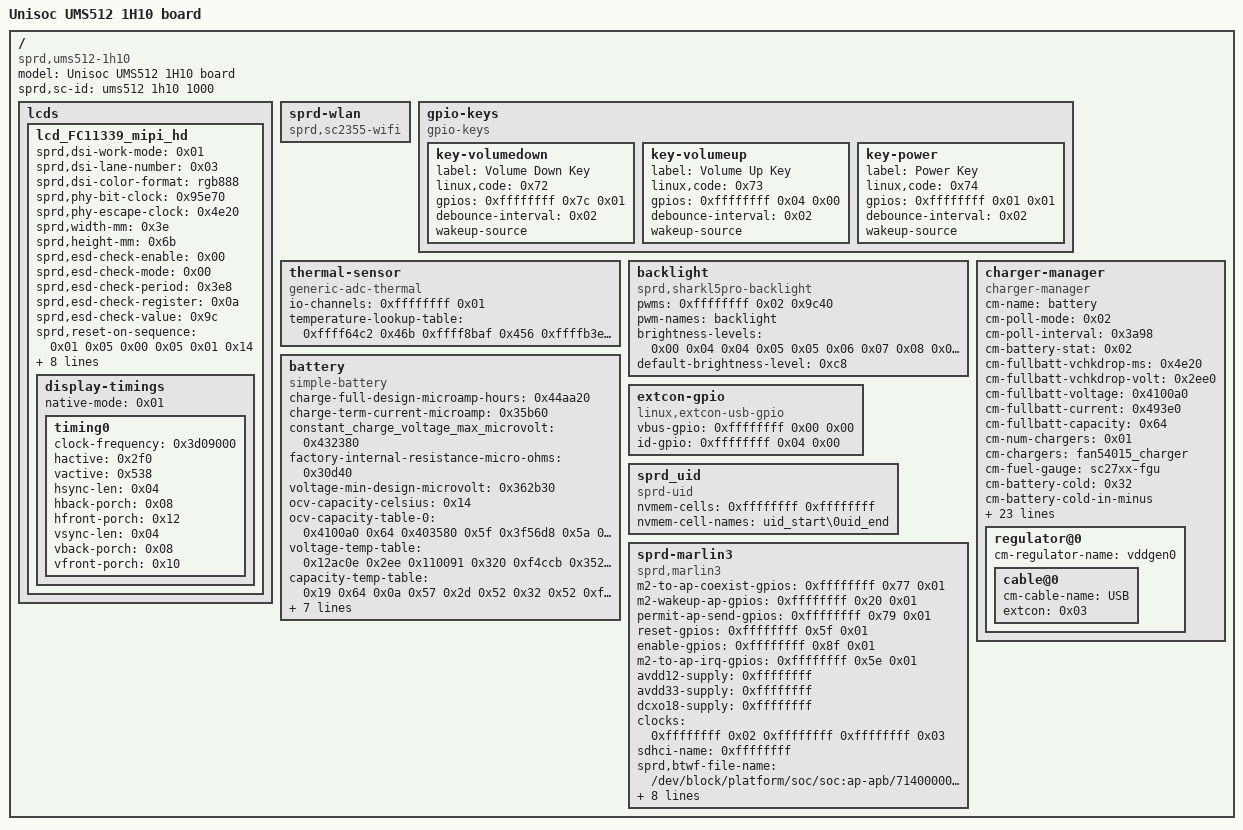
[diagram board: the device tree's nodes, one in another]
/dts-v1/;

/ {
	model = "Unisoc UMS512 1H10 board";
	compatible = "sprd,ums512-1h10";
	sprd,sc-id = "ums512 1h10 1000";

	fragment {
		target-path = "/";

		__overlay__ {

			lcds {

				lcd_FC11339_mipi_hd {
					sprd,dsi-work-mode = <0x01>;
					sprd,dsi-lane-number = <0x03>;
					sprd,dsi-color-format = "rgb888";
					sprd,phy-bit-clock = <0x95e70>;
					sprd,phy-escape-clock = <0x4e20>;
					sprd,width-mm = <0x3e>;
					sprd,height-mm = <0x6b>;
					sprd,esd-check-enable = <0x00>;
					sprd,esd-check-mode = <0x00>;
					sprd,esd-check-period = <0x3e8>;
					sprd,esd-check-register = <0x0a>;
					sprd,esd-check-value = <0x9c>;
					sprd,reset-on-sequence = <0x01 0x05 0x00 0x05 0x01 0x14>;
					sprd,reset-off-sequence = <0x00 0x05>;
					sprd,use-dcs-write;
					sprd,initial-command = [05 40 00 01 11 05 10 00 01 29];
					sprd,sleep-in-command = [15 10 00 01 28 15 40 00 01 10 29 00 00 02 b0 00 29 05 00 02 b1 01];
					sprd,sleep-out-command = [15 40 00 01 11 15 10 00 01 29 15 01 00 02 b0 00 15 01 00 02 b1 01];
					phandle = <0x18>;

					display-timings {
						native-mode = <0x01>;

						timing0 {
							clock-frequency = <0x3d09000>;
							hactive = <0x2f0>;
							vactive = <0x538>;
							hsync-len = <0x04>;
							hback-porch = <0x08>;
							hfront-porch = <0x12>;
							vsync-len = <0x04>;
							vback-porch = <0x08>;
							vfront-porch = <0x10>;
							phandle = <0x01>;
						};
					};
				};
			};

			sprd-wlan {
				compatible = "sprd,sc2355-wifi";
			};

			gpio-keys {
				compatible = "gpio-keys";

				key-volumedown {
					label = "Volume Down Key";
					linux,code = <0x72>;
					gpios = <0xffffffff 0x7c 0x01>;
					debounce-interval = <0x02>;
					wakeup-source;
				};

				key-volumeup {
					label = "Volume Up Key";
					linux,code = <0x73>;
					gpios = <0xffffffff 0x04 0x00>;
					debounce-interval = <0x02>;
					wakeup-source;
				};

				key-power {
					label = "Power Key";
					linux,code = <0x74>;
					gpios = <0xffffffff 0x01 0x01>;
					debounce-interval = <0x02>;
					wakeup-source;
				};
			};

			thermal-sensor {
				compatible = "generic-adc-thermal";
				#thermal-sensor-cells = <0x00>;
				io-channels = <0xffffffff 0x01>;
				io-channel-names = "sensor-channel";
				temperature-lookup-table = <0xffff64c2 0x46b 0xffff8baf 0x456 0xffffb3e8 0x432 0xffffedb9 0x3d7 0x277e 0x346 0x60e5 0x28e 0xaf7a 0x19d 0xd677 0x13c 0xfd7f 0xee 0x12484 0xb2 0x14b93 0x85 0x172a3 0x64 0x199b0 0x4b 0x1c0c9 0x39 0x1e7c8 0x2b>;
				phandle = <0x0f>;
			};

			backlight {
				compatible = "sprd,sharkl5pro-backlight";
				pwms = <0xffffffff 0x02 0x9c40>;
				pwm-names = "backlight";
				brightness-levels = <0x00 0x04 0x04 0x05 0x05 0x06 0x07 0x08 0x09 0x0a 0x0b 0x0c 0x0d 0x0e 0x0f 0x10 0x11 0x12 0x13 0x14 0x15 0x16 0x17 0x18 0x19 0x1a 0x1b 0x1c 0x1d 0x1e 0x1f 0x20 0x21 0x22 0x23 0x24 0x25 0x26 0x27 0x28 0x29 0x2a 0x2b 0x2c 0x2d 0x2e 0x2f 0x30 0x31 0x32 0x33 0x34 0x35 0x36 0x37 0x38 0x39 0x3a 0x3b 0x3c 0x3d 0x3e 0x3f 0x40 0x41 0x42 0x43 0x44 0x45 0x46 0x47 0x48 0x49 0x4a 0x4b 0x4c 0x4d 0x4e 0x4f 0x50 0x51 0x52 0x53 0x54 0x55 0x56 0x57 0x58 0x59 0x5a 0x5b 0x5c 0x5d 0x5e 0x5f 0x60 0x61 0x62 0x63 0x64 0x65 0x66 0x67 0x68 0x69 0x6a 0x6b 0x6c 0x6d 0x6e 0x6f 0x70 0x71 0x72 0x73 0x74 0x75 0x76 0x77 0x78 0x79 0x7a 0x7b 0x7c 0x7d 0x7e 0x7f 0x80 0x81 0x82 0x83 0x84 0x85 0x86 0x87 0x88 0x89 0x8a 0x8b 0x8c 0x8d 0x8e 0x8f 0x90 0x91 0x92 0x93 0x94 0x95 0x96 0x97 0x98 0x99 0x9a 0x9b 0x9c 0x9d 0x9e 0x9f 0xa0 0xa1 0xa2 0xa3 0xa4 0xa5 0xa6 0xa7 0xa8 0xa9 0xaa 0xab 0xac 0xad 0xae 0xaf 0xb0 0xb1 0xb2 0xb3 0xb4 0xb5 0xb6 0xb7 0xb8 0xb9 0xba 0xbb 0xbc 0xbd 0xbe 0xbf 0xc0 0xc1 0xc2 0xc3 0xc4 0xc5 0xc6 0xc7 0xc8 0xc9 0xca 0xcb 0xcc 0xcd 0xce 0xcf 0xd0 0xd1 0xd2 0xd3 0xd4 0xd5 0xd6 0xd7 0xd8 0xd9 0xda 0xdb 0xdc 0xdd 0xde 0xdf 0xe0 0xe1 0xe2 0xe3 0xe4 0xe5 0xe6 0xe7 0xe8 0xe9 0xea 0xeb 0xec 0xed 0xee 0xef 0xf0 0xf1 0xf2 0xf3 0xf4 0xf5 0xf6 0xf7 0xf8 0xf9 0xfa 0xfb 0xfc 0xfd 0xfd 0xfe 0xff>;
				default-brightness-level = <0xc8>;
				phandle = <0x14>;
			};

			battery {
				compatible = "simple-battery";
				charge-full-design-microamp-hours = <0x44aa20>;
				charge-term-current-microamp = <0x35b60>;
				constant_charge_voltage_max_microvolt = <0x432380>;
				factory-internal-resistance-micro-ohms = <0x30d40>;
				voltage-min-design-microvolt = <0x362b30>;
				ocv-capacity-celsius = <0x14>;
				ocv-capacity-table-0 = <0x4100a0 0x64 0x403580 0x5f 0x3f56d8 0x5a 0x3e83e8 0x55 0x3dbcb0 0x50 0x3d18a0 0x4b 0x4b9790 0x46 0x3bb528 0x41 0x3b2888 0x3c 0x3a8478 0x37 0x3a0390 0x32 0x39a1e8 0x2d 0x394fe0 0x28 0x391160 0x23 0x38dab0 0x1e 0x38b788 0x19 0x3884c0 0x14 0x384258 0x0f 0x37d8e0 0x0a 0x376f68 0x05 0x372918 0x00>;
				voltage-temp-table = <0x12ac0e 0x2ee 0x110091 0x320 0xf4ccb 0x352 0xd9e5a 0x384 0xc00db 0x3b6 0xa7dce 0x3e8 0x91a60 0x41a 0x7dba1 0x44c 0x6c0da 0x47e 0x5c97e 0x4b0 0x4f3d1 0x4e2 0x43ca3 0x514 0x39f71 0x546 0x319d3 0x578 0x2a7c0 0x5aa 0x247b8 0x5dc 0x1f62e 0x60e 0x1b198 0x640 0x176aa 0x672 0x1448a 0x6a4 0x11a34 0x6d6 0xf687 0x708>;
				capacity-temp-table = <0x19 0x64 0x0a 0x57 0x2d 0x52 0x32 0x52 0xfffffff6 0x58>;
				resistance-temp-table = <0x19 0x64 0x0a 0xb4 0x2d 0x31 0x32 0x29 0xfffffff6 0x1a4>;
				charge-sdp-current-microamp = <0x225510 0x16e360>;
				charge-dcp-current-microamp = <0x225510 0x1e8480>;
				charge-cdp-current-microamp = <0x225510 0x16e360>;
				charge-unknown-current-microamp = <0x225510 0x16e360>;
				phandle = <0x02>;
			};

			charger-manager {
				compatible = "charger-manager";
				cm-name = "battery";
				cm-poll-mode = <0x02>;
				cm-poll-interval = <0x3a98>;
				cm-battery-stat = <0x02>;
				cm-fullbatt-vchkdrop-ms = <0x4e20>;
				cm-fullbatt-vchkdrop-volt = <0x2ee0>;
				cm-fullbatt-voltage = <0x4100a0>;
				cm-fullbatt-current = <0x493e0>;
				cm-fullbatt-capacity = <0x64>;
				cm-num-chargers = <0x01>;
				cm-chargers = "fan54015_charger";
				cm-fuel-gauge = "sc27xx-fgu";
				cm-battery-cold = <0x32>;
				cm-battery-cold-in-minus;
				cm-battery-hot = <0x28a>;
				cm-battery-temp-diff = <0x32>;
				cm-charging-max = <0x112a880>;
				cm-discharging-max = <0x2932e0>;
				cm-wdt-interval = <0x3c>;
				cm-shutdown-voltage = <0x2f4d60>;
				cm-tickle-time-out = <0x258>;
				cm-one-cap-time = <0x1e>;
				cm-thermal-zone = "board-thmzone";
				cm-charge-voltage-max = <0x632ea0>;
				cm-charge-voltage-drop = <0xaae60>;
				cm-dcp-jeita-temp-table = <0x3e8 0x406 0x00 0x432380 0x47e 0x49c 0xaae60 0x432380 0x5aa 0x58c 0x225510 0x432380 0x640 0x622 0xaae60 0x3e8fa0>;
				cm-sdp-jeita-temp-table = <0x3e8 0x406 0x00 0x432380 0x47e 0x49c 0x7a120 0x432380 0x5aa 0x58c 0x225510 0x432380 0x640 0x622 0x7a120 0x3e8fa0>;
				cm-cdp-jeita-temp-table = <0x3e8 0x406 0x00 0x432380 0x47e 0x49c 0xaae60 0x432380 0x5aa 0x58c 0x225510 0x432380 0x640 0x622 0xaae60 0x3e8fa0>;
				cm-unknown-jeita-temp-table = <0x3e8 0x406 0x00 0x432380 0x47e 0x49c 0x7a120 0x432380 0x5aa 0x58c 0x225510 0x432380 0x640 0x622 0x7a120 0x3e8fa0>;
				monitored-battery = <0x02>;
				cm-capacity-track;
				cm-cap-remap-table = <0x01 0x02 0x02 0x02 0x03 0x01 0x62 0x63 0x02 0x63 0x64 0x02>;

				regulator@0 {
					cm-regulator-name = "vddgen0";

					cable@0 {
						cm-cable-name = "USB";
						extcon = <0x03>;
					};
				};
			};

			extcon-gpio {
				compatible = "linux,extcon-usb-gpio";
				vbus-gpio = <0xffffffff 0x00 0x00>;
				id-gpio = <0xffffffff 0x04 0x00>;
				phandle = <0x03>;
			};

			sprd_uid {
				compatible = "sprd-uid";
				nvmem-cells = <0xffffffff 0xffffffff>;
				nvmem-cell-names = "uid_start\0uid_end";
			};

			sprd-marlin3 {
				compatible = "sprd,marlin3";
				m2-to-ap-coexist-gpios = <0xffffffff 0x77 0x01>;
				m2-wakeup-ap-gpios = <0xffffffff 0x20 0x01>;
				permit-ap-send-gpios = <0xffffffff 0x79 0x01>;
				reset-gpios = <0xffffffff 0x5f 0x01>;
				enable-gpios = <0xffffffff 0x8f 0x01>;
				m2-to-ap-irq-gpios = <0xffffffff 0x5e 0x01>;
				avdd12-supply = <0xffffffff>;
				avdd33-supply = <0xffffffff>;
				dcxo18-supply = <0xffffffff>;
				clock-names = "clk_32k\0source\0enable";
				clocks = <0xffffffff 0x02 0xffffffff 0xffffffff 0x03>;
				sdhci-name = <0xffffffff>;
				sprd,btwf-file-name = "/dev/block/platform/soc/soc:ap-apb/71400000.sdio/by-name/wcnmodem";
				sprd,gnss-file-name = "/dev/block/platform/soc/soc:ap-apb/71400000.sdio/by-name/gnssmodem";
				adma-tx;
				adma-rx;
				avdd12-parent-bound-chip = <0x1a4c 0x01 0x00 0x01>;
				avdd12-bound-wbreq = <0x1ac8 0x1000 0x00 0x1000>;
				avdd33-bound-wbreq = <0x1acc 0x04 0x00 0x04>;
				phandle = <0x19>;
			};
		};
	};

	fragment@0 {
		target = <0xffffffff>;

		__overlay__ {
			bootargs_ext = "androidboot.hardware=ums512_1h10 androidboot.dtbo_idx=0";
		};
	};

	fragment@1 {
		target = <0xffffffff>;

		__overlay__ {

			logobuffer@9e000000 {
				reg = <0x00 0x9e000000 0x00 0x9e4000>;
				phandle = <0x17>;
			};

			drm-mem@e32ae000 {
				reg = <0x00 0xe32ae000 0x00 0xc800000>;
				phandle = <0x10>;
			};

			faceid-mem@efaae000 {
				reg = <0x00 0xefaae000 0x00 0x500000>;
				phandle = <0x11>;
			};

			vdsp-mem@f09ae000 {
				reg = <0x00 0xf09ae000 0x00 0x3700000>;
				phandle = <0x12>;
			};

			framebuffer-mem@fd708000 {
				reg = <0x00 0xfd708000 0x00 0x1e5a000>;
				phandle = <0x15>;
			};

			writeback-mem@ff562000 {
				reg = <0x00 0xff562000 0x00 0xa1e000>;
				phandle = <0x16>;
			};
		};
	};

	fragment@2 {
		target = <0xffffffff>;

		__overlay__ {
			cd-gpios = <0xffffffff 0x13 0x01>;
		};
	};

	fragment@3 {
		target = <0xffffffff>;

		__overlay__ {
			pinctrl-names = "gpio_121\0gpio_122\0gpio_123\0gpio_124\0gpio_125\0gpio_126\0gpio_144\0gpio_145\0gpio_146\0gpio_147\0gpio_16";
			pinctrl-0 = <0x04>;
			pinctrl-1 = <0x05>;
			pinctrl-2 = <0x06>;
			pinctrl-3 = <0x07>;
			pinctrl-4 = <0x08>;
			pinctrl-5 = <0x09>;
			pinctrl-6 = <0x0a>;
			pinctrl-7 = <0x0b>;
			pinctrl-8 = <0x0c>;
			pinctrl-9 = <0x0d>;
			pinctrl-10 = <0x0e>;

			keyout0 {
				pins = "SHARKL5PRO_KEYOUT0";
				function = "func4";
				phandle = <0x04>;
			};

			keyout1 {
				pins = "SHARKL5PRO_KEYOUT1";
				function = "func4";
				phandle = <0x05>;
			};

			keyout2 {
				pins = "SHARKL5PRO_KEYOUT2";
				function = "func4";
				phandle = <0x06>;
			};

			keyin0 {
				pins = "SHARKL5PRO_KEYIN0";
				function = "func4";
				phandle = <0x07>;
			};

			keyin1 {
				pins = "SHARKL5PRO_KEYIN1";
				function = "func4";
				phandle = <0x08>;
			};

			keyin2 {
				pins = "SHARKL5PRO_KEYIN2";
				function = "func4";
				phandle = <0x09>;
			};

			extint0 {
				pins = "SHARKL5PRO_EXTINT0";
				function = "func4";
				phandle = <0x0a>;
			};

			extint1 {
				pins = "SHARKL5PRO_EXTINT1";
				function = "func4";
				phandle = <0x0b>;
			};

			scl3 {
				pins = "SHARKL5PRO_SCL3";
				function = "func4";
				phandle = <0x0d>;
			};

			sda3 {
				pins = "SHARKL5PRO_SDA3";
				function = "func4";
				phandle = <0x0c>;
			};

			rffe1_sda {
				pins = "SHARKL5PRO_RFFE1_SDA";
				function = "func4";
				phandle = <0x0e>;
			};
		};
	};

	fragment@4 {
		target = <0xffffffff>;

		__overlay__ {

			board-thmzone {
				polling-delay-passive = <0x00>;
				polling-delay = <0x00>;
				thermal-sensors = <0x0f>;
				phandle = <0x1a>;
			};
		};
	};

	fragment@5 {
		target = <0xffffffff>;

		__overlay__ {

			heap@1 {
				reg = <0x01>;
				label = "carveout_mm";
				type = <0x02>;
				memory-region = <0x10>;
			};

			heap@4 {
				reg = <0x04>;
				label = "carveout_fd";
				type = <0x02>;
				memory-region = <0x11>;
			};

			heap@5 {
				reg = <0x05>;
				label = "carveout_vdsp";
				type = <0x02>;
				memory-region = <0x12>;
			};
		};
	};

	fragment@6 {
		target = <0xffffffff>;

		__overlay__ {
			status = "okay";
			clock-frequency = <0x61a80>;

			sensor-main@20 {
				compatible = "sprd,sensor-main";
				reg = <0x20>;
				clock-names = "clk_src\0sensor_eb\0clk_96m\0clk_76m8\0clk_48m\0clk_26m";
				clocks = <0xffffffff 0x02 0xffffffff 0x0d 0xffffffff 0x04 0xffffffff 0x10 0xffffffff 0x05 0xffffffff>;
				vddio-supply = <0xffffffff>;
				vddcama-supply = <0xffffffff>;
				vddcamd-supply = <0xffffffff>;
				vddcammot-supply = <0xffffffff>;
				avdd-gpios = <0xffffffff 0x19 0x00>;
				dvdd-gpios = <0xffffffff 0x0f 0x00>;
				reset-gpios = <0xffffffff 0x2c 0x00>;
				power-down-gpios = <0xffffffff 0x2e 0x00>;
				sprd,phyid = <0x00>;
				csi = <0xffffffff>;
				phandle = <0x1b>;
			};

			deputy-camera@21 {
				compatible = "deputy_camera, deputy_camera_i2c";
				reg = <0x21>;
				power_down_gpios_b = <0xffffffff 0x2e 0x00>;
				phandle = <0x1c>;
			};
		};
	};

	fragment@7 {
		target = <0xffffffff>;

		__overlay__ {
			status = "okay";
			clock-frequency = <0x61a80>;

			sensor-sub@6C {
				compatible = "sprd,sensor-sub";
				reg = <0x6c>;
				clock-names = "clk_src\0sensor_eb\0clk_96m\0clk_76m8\0clk_48m\0clk_26m";
				clocks = <0xffffffff 0x03 0xffffffff 0x0c 0xffffffff 0x04 0xffffffff 0x10 0xffffffff 0x05 0xffffffff>;
				vddio-supply = <0xffffffff>;
				vddcama-supply = <0xffffffff>;
				vddcamd-supply = <0xffffffff>;
				avdd-gpios = <0xffffffff 0x19 0x00>;
				dvdd-gpios = <0xffffffff 0x0f 0x00>;
				reset-gpios = <0xffffffff 0x29 0x00>;
				sprd,phyid = <0x04>;
				csi = <0xffffffff>;
				phandle = <0x1d>;
			};

			sensor-main2@2a {
				compatible = "sprd,sensor-main2";
				reg = <0x2a>;
				clock-names = "clk_src\0sensor_eb\0clk_96m\0clk_76m8\0clk_48m\0clk_26m";
				clocks = <0xffffffff 0x03 0xffffffff 0x0c 0xffffffff 0x04 0xffffffff 0x10 0xffffffff 0x05 0xffffffff>;
				vddio-supply = <0xffffffff>;
				vddcama-supply = <0xffffffff>;
				vddcamd-supply = <0xffffffff>;
				vddcammot-supply = <0xffffffff>;
				reset-gpios = <0xffffffff 0x29 0x00>;
				sprd,phyid = <0x02>;
				csi = <0xffffffff>;
				status = "okay";
				phandle = <0x1e>;
			};
		};
	};

	fragment@8 {
		target = <0xffffffff>;

		__overlay__ {
			status = "okay";
			clock-frequency = <0x61a80>;
		};
	};

	fragment@9 {
		target = <0xffffffff>;

		__overlay__ {
			status = "okay";

			hynitron-ts@5a {
				compatible = "hynitron,cst1xx";
				reg = <0x5a>;
				hynitron,panel-coords = <0x00 0x438 0x00 0x870>;
				hynitron,display-coords = <0x00 0x438 0x00 0x870>;
				hynitron,irq-gpio = <0xffffffff 0x90 0x00>;
				hynitron,rst-gpio = <0xffffffff 0x91 0x00>;
				report_type = <0x01>;
				status = "okay";
			};
		};
	};

	fragment@10 {
		target = <0xffffffff>;

		__overlay__ {
			status = "okay";

			charger@6a {
				compatible = "fairchild,fan54015_chg";
				reg = <0x6a>;
				phys = <0xffffffff>;
				monitored-battery = <0x02>;
				extcon = <0x03>;
				phandle = <0x1f>;

				otg-vbus {
					regulator-name = "vddvbus";
					phandle = <0x13>;
				};
			};
		};
	};

	fragment@11 {
		target = <0xffffffff>;

		__overlay__ {
			vdd-supply = <0xffffffff>;
			extcon = <0x03>;
		};
	};

	fragment@12 {
		target = <0xffffffff>;

		__overlay__ {
			extcon = <0x03>;
			vbus-supply = <0x13>;
		};
	};

	fragment@13 {
		target = <0xffffffff>;

		__overlay__ {
			status = "okay";
			clock-frequency = <0xf4240>;

			cpudvfs-dcdc-cpu1@62 {
				compatible = "sprd,cpudvfs-regulator-sharkl5pro";
				reg = <0x62>;
				dvfs-dcdc-i2c = <0x01>;
			};

			eta355e_dcdc_cpu1@60 {
				compatible = "eta355e,dcdc-cpu1";
				reg = <0x60>;
			};
		};
	};

	fragment@14 {
		target = <0xffffffff>;

		__overlay__ {
			sprd,backlight = <0x14>;
			avdd-gpio = <0xffffffff 0x85 0x00>;
			reset-gpio = <0xffffffff 0x32 0x00>;
		};
	};

	fragment@15 {
		target = <0xffffffff>;

		__overlay__ {
			sprd,backlight = <0x14>;
		};
	};

	fragment@16 {
		target = <0xffffffff>;

		__overlay__ {
			sprd-scene = "boost\0lcdon\0lcdoff\0camlow\0camhigh\0camveryhigh\0faceid";
			sprd-freq = <0x535 0x300 0x100 0x180 0x200 0xbacd 0x535>;
		};
	};

	fragment@17 {
		target = <0xffffffff>;

		__overlay__ {
			monitored-battery = <0x02>;
			sprd,calib-resistance-real = <0x2710>;
			sprd,calib-resistance-spec = <0x4e20>;
			first-calib-voltage = <0x3763b0>;
			first-calib-capacity = <0x28>;
		};
	};

	fragment@18 {
		target = <0xffffffff>;

		__overlay__ {
			extcon = <0x03 0xffffffff>;
			vbus-supply = <0x13>;
		};
	};

	fragment@19 {
		target = <0xffffffff>;

		__overlay__ {
			regulator-always-on;
		};
	};

	fragment@20 {
		target = <0xffffffff>;

		__overlay__ {
			sprd,hw-channels = <0x02 0x18cc 0x03 0x18cc 0x0d 0x1874 0x0f 0x1874 0x11 0x1844 0x13 0x1854 0x15 0x1864 0x1e 0x1820 0x23 0x19b8 0x27 0x19ac>;
		};
	};

	fragment@21 {
		target = <0xffffffff>;

		__overlay__ {
			pmic-type-num = <0x00>;
			slew-rate = <0x249f>;
			top-dvfs-adi-state = <0x70 0x00 0x0f>;
			voltage-grade-num = <0x07>;
			voltage-grade = <0x00 0xf0 0xf4 0x00 0x1ff 0x01 0xf0 0xf4 0x09 0x1ff 0x02 0x100 0xf4 0x12 0x1ff 0x03 0x110 0xf8 0x00 0x1ff 0x04 0x120 0xf8 0x09 0x1ff 0x05 0x130 0xf8 0x12 0x1ff 0x06 0x140 0xfc 0x00 0x1ff>;
			voltage-up-delay = <0x32 0x58 0x00 0xffff 0x600 0x64 0x58 0x10 0xffff 0xa00 0x96 0x54 0x00 0xffff 0xf00 0xc8 0x54 0x10 0xffff 0x1400 0xfa 0x50 0x00 0xffff 0x1900 0x12c 0x50 0x10 0xffff 0x1e00 0x15e 0x110 0x00 0xffff 0x2300>;
			voltage-down-delay = <0x32 0x64 0x00 0xffff 0x600 0x64 0x64 0x10 0xffff 0xa00 0x96 0x60 0x00 0xffff 0xf00 0xc8 0x60 0x10 0xffff 0x1400 0xfa 0x5c 0x00 0xffff 0x1900 0x12c 0x5c 0x10 0xffff 0x1e00 0x15e 0x114 0x00 0xffff 0x2300>;
			tuning-latency-us = <0x00>;
			chnl-in-i2c = <0x00>;
		};
	};

	fragment@22 {
		target = <0xffffffff>;

		__overlay__ {
			pmic-type-num = <0x00>;
			slew-rate = <0x249f>;
			supply-type-sel = <0x120 0x00 0x00>;
			top-dvfs-adi-state = <0x9c 0x00 0x0f>;
			voltage-grade-num = <0x06>;
			voltage-grade = <0x00 0xf0 0x100 0x00 0x1ff 0x01 0x100 0x100 0x09 0x1ff 0x02 0x110 0x100 0x12 0x1ff 0x03 0x120 0x104 0x00 0x1ff 0x04 0x130 0x104 0x09 0x1ff 0x05 0x140 0x104 0x12 0x1ff>;
			voltage-up-delay = <0x32 0x84 0x00 0xffff 0x1600 0x64 0x84 0x10 0xffff 0xa00 0x96 0x80 0x00 0xffff 0x1f00 0xc8 0x80 0x10 0xffff 0x1400 0xfa 0x7c 0x00 0xffff 0x1900 0x12c 0x7c 0x10 0xffff 0x1e00 0x15e 0x118 0x00 0xffff 0x2300>;
			voltage-down-delay = <0x32 0x90 0x00 0xffff 0x600 0x64 0x90 0x10 0xffff 0xa00 0x96 0x8c 0x00 0xffff 0xf00 0xc8 0x8c 0x10 0xffff 0x1400 0xfa 0x88 0x00 0xffff 0x1900 0x12c 0x88 0x10 0xffff 0x1e00 0x15e 0x11c 0x00 0xffff 0x2300>;
			tuning-latency-us = <0xc8>;
			chnl-in-i2c = <0x00>;
		};
	};

	fragment@23 {
		target = <0xffffffff>;

		__overlay__ {

			heap@3 {
				reg = <0x03>;
				label = "carveout_fb";
				type = <0x02>;
				memory-region = <0x15>;
			};
		};
	};

	fragment@24 {
		target = <0xffffffff>;

		__overlay__ {
			sprd,wb-memory = <0x16>;
			sprd,logo-memory = <0x17>;
		};
	};

	__symbols__ {
		lcd_FC11339_mipi_hd = "/fragment/__overlay__/lcds/lcd_FC11339_mipi_hd";
		FC11339_truly_timing0 = "/fragment/__overlay__/lcds/lcd_FC11339_mipi_hd/display-timings/timing0";
		tboard_thermistor = "/fragment/__overlay__/thermal-sensor";
		pwm_backlight = "/fragment/__overlay__/backlight";
		bat = "/fragment/__overlay__/battery";
		extcon_gpio = "/fragment/__overlay__/extcon-gpio";
		sprd_marlin3 = "/fragment/__overlay__/sprd-marlin3";
		logo_reserved = "/fragment@1/__overlay__/logobuffer@9e000000";
		drm_reserved = "/fragment@1/__overlay__/drm-mem@e32ae000";
		fd_reserved = "/fragment@1/__overlay__/faceid-mem@efaae000";
		vdsp_reserved = "/fragment@1/__overlay__/vdsp-mem@f09ae000";
		fb_reserved = "/fragment@1/__overlay__/framebuffer-mem@fd708000";
		wb_reserved = "/fragment@1/__overlay__/writeback-mem@ff562000";
		gpio_121 = "/fragment@3/__overlay__/keyout0";
		gpio_122 = "/fragment@3/__overlay__/keyout1";
		gpio_123 = "/fragment@3/__overlay__/keyout2";
		gpio_124 = "/fragment@3/__overlay__/keyin0";
		gpio_125 = "/fragment@3/__overlay__/keyin1";
		gpio_126 = "/fragment@3/__overlay__/keyin2";
		gpio_144 = "/fragment@3/__overlay__/extint0";
		gpio_145 = "/fragment@3/__overlay__/extint1";
		gpio_147 = "/fragment@3/__overlay__/scl3";
		gpio_146 = "/fragment@3/__overlay__/sda3";
		gpio_16 = "/fragment@3/__overlay__/rffe1_sda";
		bd_thmzone = "/fragment@4/__overlay__/board-thmzone";
		sensor_main = "/fragment@6/__overlay__/sensor-main@20";
		deputy_camera = "/fragment@6/__overlay__/deputy-camera@21";
		sensor_sub = "/fragment@7/__overlay__/sensor-sub@6C";
		sensor_main2 = "/fragment@7/__overlay__/sensor-main2@2a";
		fan54015_chg = "/fragment@10/__overlay__/charger@6a";
		vddvbus = "/fragment@10/__overlay__/charger@6a/otg-vbus";
	};

	__fixups__ {
		ap_gpio = "/fragment/__overlay__/gpio-keys/key-volumedown:gpios:0\0/fragment/__overlay__/sprd-marlin3:m2-to-ap-coexist-gpios:0\0/fragment/__overlay__/sprd-marlin3:m2-wakeup-ap-gpios:0\0/fragment/__overlay__/sprd-marlin3:permit-ap-send-gpios:0\0/fragment/__overlay__/sprd-marlin3:reset-gpios:0\0/fragment/__overlay__/sprd-marlin3:enable-gpios:0\0/fragment/__overlay__/sprd-marlin3:m2-to-ap-irq-gpios:0\0/fragment@6/__overlay__/sensor-main@20:avdd-gpios:0\0/fragment@6/__overlay__/sensor-main@20:dvdd-gpios:0\0/fragment@6/__overlay__/sensor-main@20:reset-gpios:0\0/fragment@6/__overlay__/sensor-main@20:power-down-gpios:0\0/fragment@6/__overlay__/deputy-camera@21:power_down_gpios_b:0\0/fragment@7/__overlay__/sensor-sub@6C:avdd-gpios:0\0/fragment@7/__overlay__/sensor-sub@6C:dvdd-gpios:0\0/fragment@7/__overlay__/sensor-sub@6C:reset-gpios:0\0/fragment@7/__overlay__/sensor-main2@2a:reset-gpios:0\0/fragment@9/__overlay__/hynitron-ts@5a:hynitron,irq-gpio:0\0/fragment@9/__overlay__/hynitron-ts@5a:hynitron,rst-gpio:0\0/fragment@14/__overlay__:avdd-gpio:0\0/fragment@14/__overlay__:reset-gpio:0";
		pmic_eic = "/fragment/__overlay__/gpio-keys/key-volumeup:gpios:0\0/fragment/__overlay__/gpio-keys/key-power:gpios:0\0/fragment/__overlay__/extcon-gpio:vbus-gpio:0";
		pmic_adc = "/fragment/__overlay__/thermal-sensor:io-channels:0";
		pwms = "/fragment/__overlay__/backlight:pwms:0";
		eic_debounce = "/fragment/__overlay__/extcon-gpio:id-gpio:0";
		uid_start = "/fragment/__overlay__/sprd_uid:nvmem-cells:0";
		uid_end = "/fragment/__overlay__/sprd_uid:nvmem-cells:4";
		vddwcn = "/fragment/__overlay__/sprd-marlin3:avdd12-supply:0";
		vddwifipa = "/fragment/__overlay__/sprd-marlin3:avdd33-supply:0";
		vddsim2 = "/fragment/__overlay__/sprd-marlin3:dcxo18-supply:0";
		aon_clk = "/fragment/__overlay__/sprd-marlin3:clocks:0";
		ext_32k = "/fragment/__overlay__/sprd-marlin3:clocks:8";
		aonapb_gate = "/fragment/__overlay__/sprd-marlin3:clocks:12";
		sdio1 = "/fragment/__overlay__/sprd-marlin3:sdhci-name:0";
		chosen = "/fragment@0:target:0";
		reserved_memory = "/fragment@1:target:0";
		sdio0 = "/fragment@2:target:0";
		eic_sync = "/fragment@2/__overlay__:cd-gpios:0";
		pin_controller = "/fragment@3:target:0";
		thm_zone = "/fragment@4:target:0";
		ion = "/fragment@5:target:0\0/fragment@23:target:0";
		i2c0 = "/fragment@6:target:0";
		mm_clk = "/fragment@6/__overlay__/sensor-main@20:clocks:0\0/fragment@7/__overlay__/sensor-sub@6C:clocks:0\0/fragment@7/__overlay__/sensor-main2@2a:clocks:0";
		mm_gate = "/fragment@6/__overlay__/sensor-main@20:clocks:8\0/fragment@7/__overlay__/sensor-sub@6C:clocks:8\0/fragment@7/__overlay__/sensor-main2@2a:clocks:8";
		pll2 = "/fragment@6/__overlay__/sensor-main@20:clocks:16\0/fragment@6/__overlay__/sensor-main@20:clocks:24\0/fragment@6/__overlay__/sensor-main@20:clocks:32\0/fragment@7/__overlay__/sensor-sub@6C:clocks:16\0/fragment@7/__overlay__/sensor-sub@6C:clocks:24\0/fragment@7/__overlay__/sensor-sub@6C:clocks:32\0/fragment@7/__overlay__/sensor-main2@2a:clocks:16\0/fragment@7/__overlay__/sensor-main2@2a:clocks:24\0/fragment@7/__overlay__/sensor-main2@2a:clocks:32";
		ext_26m = "/fragment@6/__overlay__/sensor-main@20:clocks:40\0/fragment@7/__overlay__/sensor-sub@6C:clocks:40\0/fragment@7/__overlay__/sensor-main2@2a:clocks:40";
		vddcamio = "/fragment@6/__overlay__/sensor-main@20:vddio-supply:0\0/fragment@7/__overlay__/sensor-sub@6C:vddio-supply:0\0/fragment@7/__overlay__/sensor-main2@2a:vddio-supply:0";
		vddcama0 = "/fragment@6/__overlay__/sensor-main@20:vddcama-supply:0\0/fragment@7/__overlay__/sensor-sub@6C:vddcama-supply:0";
		vddcamd0 = "/fragment@6/__overlay__/sensor-main@20:vddcamd-supply:0\0/fragment@7/__overlay__/sensor-sub@6C:vddcamd-supply:0";
		vddcammot = "/fragment@6/__overlay__/sensor-main@20:vddcammot-supply:0\0/fragment@7/__overlay__/sensor-main2@2a:vddcammot-supply:0";
		csi0 = "/fragment@6/__overlay__/sensor-main@20:csi:0";
		i2c1 = "/fragment@7:target:0";
		csi1 = "/fragment@7/__overlay__/sensor-sub@6C:csi:0\0/fragment@7/__overlay__/sensor-main2@2a:csi:0";
		vddcama1 = "/fragment@7/__overlay__/sensor-main2@2a:vddcama-supply:0";
		vddcamd1 = "/fragment@7/__overlay__/sensor-main2@2a:vddcamd-supply:0";
		i2c2 = "/fragment@8:target:0";
		i2c3 = "/fragment@9:target:0";
		i2c4 = "/fragment@10:target:0";
		hsphy = "/fragment@10/__overlay__/charger@6a:phys:0\0/fragment@11:target:0";
		vddusb33 = "/fragment@11/__overlay__:vdd-supply:0";
		usb = "/fragment@12:target:0\0/fragment@18:target:0";
		aon_i2c0 = "/fragment@13:target:0";
		panel = "/fragment@14:target:0";
		dpu = "/fragment@15:target:0\0/fragment@24:target:0";
		ddr_dfs = "/fragment@16:target:0";
		pmic_fgu = "/fragment@17:target:0";
		pmic_typec = "/fragment@18/__overlay__:extcon:4";
		vddldo0 = "/fragment@19:target:0";
		adi_bus = "/fragment@20:target:0";
		dvfs_dcdc_cpu0_supply = "/fragment@21:target:0";
		dvfs_dcdc_cpu1_supply = "/fragment@22:target:0";
	};

	__local_fixups__ {

		fragment {

			__overlay__ {

				lcds {

					lcd_FC11339_mipi_hd {

						display-timings {
							native-mode = <0x00>;
						};
					};
				};

				charger-manager {
					monitored-battery = <0x00>;

					regulator@0 {

						cable@0 {
							extcon = <0x00>;
						};
					};
				};
			};
		};

		fragment@3 {

			__overlay__ {
				pinctrl-0 = <0x00>;
				pinctrl-1 = <0x00>;
				pinctrl-2 = <0x00>;
				pinctrl-3 = <0x00>;
				pinctrl-4 = <0x00>;
				pinctrl-5 = <0x00>;
				pinctrl-6 = <0x00>;
				pinctrl-7 = <0x00>;
				pinctrl-8 = <0x00>;
				pinctrl-9 = <0x00>;
				pinctrl-10 = <0x00>;
			};
		};

		fragment@4 {

			__overlay__ {

				board-thmzone {
					thermal-sensors = <0x00>;
				};
			};
		};

		fragment@5 {

			__overlay__ {

				heap@1 {
					memory-region = <0x00>;
				};

				heap@4 {
					memory-region = <0x00>;
				};

				heap@5 {
					memory-region = <0x00>;
				};
			};
		};

		fragment@10 {

			__overlay__ {

				charger@6a {
					monitored-battery = <0x00>;
					extcon = <0x00>;
				};
			};
		};

		fragment@11 {

			__overlay__ {
				extcon = <0x00>;
			};
		};

		fragment@12 {

			__overlay__ {
				extcon = <0x00>;
				vbus-supply = <0x00>;
			};
		};

		fragment@14 {

			__overlay__ {
				sprd,backlight = <0x00>;
			};
		};

		fragment@15 {

			__overlay__ {
				sprd,backlight = <0x00>;
			};
		};

		fragment@17 {

			__overlay__ {
				monitored-battery = <0x00>;
			};
		};

		fragment@18 {

			__overlay__ {
				extcon = <0x00>;
				vbus-supply = <0x00>;
			};
		};

		fragment@23 {

			__overlay__ {

				heap@3 {
					memory-region = <0x00>;
				};
			};
		};

		fragment@24 {

			__overlay__ {
				sprd,wb-memory = <0x00>;
				sprd,logo-memory = <0x00>;
			};
		};
	};
};
